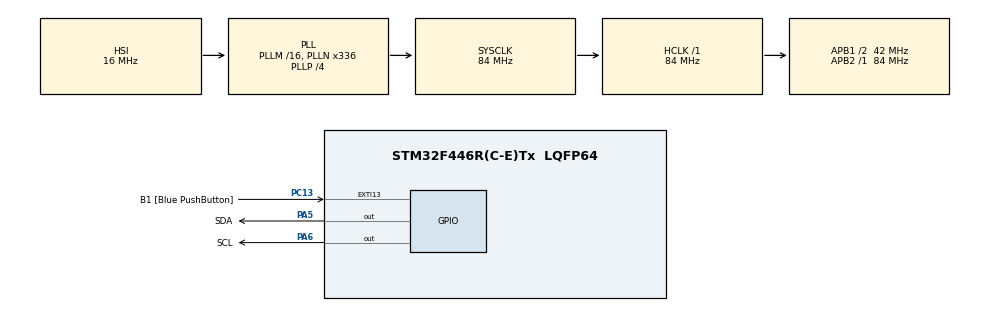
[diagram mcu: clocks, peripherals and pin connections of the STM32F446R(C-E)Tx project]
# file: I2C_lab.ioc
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Mcu.Family=STM32F4
Mcu.Name=STM32F446R(C-E)Tx
Mcu.Package=LQFP64
NVIC.PriorityGroup=NVIC_PRIORITYGROUP_0
NVIC.TIM1_UP_TIM10_IRQn=true\:0\:0\:false\:false\:true\:true\:true\:true
PA13.GPIO_Label=TMS
PA13.Mode=Serial_Wire
PA13.Signal=SYS_JTMS-SWDIO
PA14.GPIO_Label=TCK
PA14.Mode=Serial_Wire
PA14.Signal=SYS_JTCK-SWCLK
PA5.GPIO_Label=SDA
PA5.GPIO_ModeDefaultOutputPP=GPIO_MODE_OUTPUT_OD
PA5.GPIO_PuPd=GPIO_PULLUP
PA5.PinState=GPIO_PIN_SET
PA5.Signal=GPIO_Output
PA6.GPIO_Label=SCL
PA6.GPIO_ModeDefaultOutputPP=GPIO_MODE_OUTPUT_OD
PA6.GPIO_PuPd=GPIO_PULLUP
PA6.PinState=GPIO_PIN_SET
PA6.Signal=GPIO_Output
PB3.GPIO_Label=SWO
PB3.Signal=SYS_JTDO-SWO
PC13.GPIO_Label=B1 [Blue PushButton]
PC13.GPIO_ModeDefaultEXTI=GPIO_MODE_IT_FALLING
PC13.Signal=GPXTI13
PC14-OSC32_IN.Mode=LSE-External-Oscillator
PC14-OSC32_IN.Signal=RCC_OSC32_IN
PC15-OSC32_OUT.Mode=LSE-External-Oscillator
PC15-OSC32_OUT.Signal=RCC_OSC32_OUT
PH0-OSC_IN.Mode=HSE-External-Oscillator
PH0-OSC_IN.Signal=RCC_OSC_IN
PH1-OSC_OUT.Mode=HSE-External-Oscillator
PH1-OSC_OUT.Signal=RCC_OSC_OUT
ProjectManager.HeapSize=0x200
ProjectManager.StackSize=0x400
ProjectManager.TargetToolchain=STM32CubeIDE
RCC.48MHZClocksFreq_Value=84000000
RCC.AHBFreq_Value=84000000
RCC.APB1CLKDivider=RCC_HCLK_DIV2
RCC.APB1Freq_Value=42000000
RCC.APB1TimFreq_Value=84000000
RCC.APB2Freq_Value=84000000
RCC.APB2TimFreq_Value=84000000
RCC.CortexFreq_Value=84000000
RCC.FLatency-AdvancedSettings=FLASH_LATENCY_2
RCC.HCLKFreq_Value=84000000
RCC.HSE_VALUE=8000000
RCC.HSI_VALUE=16000000
RCC.PLLN=336
RCC.PLLP=RCC_PLLP_DIV4
RCC.SYSCLKFreq_VALUE=84000000
RCC.SYSCLKSource=RCC_SYSCLKSOURCE_PLLCLK
RCC.USBFreq_Value=168000000
RCC.VCOOutputFreq_Value=336000000
TIM1.Period=499
TIM1.Prescaler=15999
TIM1.TIM_MasterOutputTrigger=TIM_TRGO_UPDATE
VP_TIM1_VS_ClockSourceINT.Mode=Internal
board=NUCLEO-F446RE

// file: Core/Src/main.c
/* USER CODE BEGIN Header */
/**
  ******************************************************************************
  * @file           : main.c
  * @brief          : Main program body
  ******************************************************************************
  * @attention
  *
  * Copyright (c) 2026 STMicroelectronics.
  * All rights reserved.
  *
  * This software is licensed under terms that can be found in the LICENSE file
  * in the root directory of this software component.
  * If no LICENSE file comes with this software, it is provided AS-IS.
  *
  ******************************************************************************
  */
/* USER CODE END Header */
#include "main.h"

/* USER CODE BEGIN PTD */
typedef enum {
    I2C_IDLE,
    I2C_SEND_ADDRESS, // consists of target + R/W bit
    I2C_WAIT_ADDRESS_ACK,
    I2C_SEND_DATA,
    I2C_WAIT_DATA_ACK,
    I2C_STOP
} I2C_State;

/* USER CODE END PTD */

TIM_HandleTypeDef htim1;

/* USER CODE BEGIN PV */
volatile uint16_t clk_cycle_position; // 0=1st half of low, 1=2nd half of low,
									  // 2=1st half of high, 3=2nd half of high

volatile I2C_State i2c_state = I2C_IDLE;
volatile int8_t bit_position;
volatile uint8_t bit;

uint8_t target_write_address = 0b10100000;
uint8_t data = 0b01010111;

/* USER CODE END PV */

void SystemClock_Config(void);
static void MX_GPIO_Init(void);
static void MX_TIM1_Init(void);

/* USER CODE BEGIN 0 */
void HAL_TIM_PeriodElapsedCallback(TIM_HandleTypeDef *htim)
{
    if (htim->Instance == TIM1) {
    	if (clk_cycle_position == 0) {
    		clk_cycle_position = 1;

    		// transmit data based on i2c_state
    		if (i2c_state == I2C_SEND_ADDRESS) {
    			if (bit_position >= 0) {
    				bit = (target_write_address >> bit_position) & 1;
    				HAL_GPIO_WritePin(GPIOA, SDA_Pin, bit == 1? GPIO_PIN_SET : GPIO_PIN_RESET);
    				bit_position--;
    			} else {
    				i2c_state = I2C_WAIT_ADDRESS_ACK;
					HAL_GPIO_WritePin(GPIOA, SDA_Pin, GPIO_PIN_SET); // release data line
    			}
    		} else if (i2c_state == I2C_WAIT_ADDRESS_ACK) {
    			if (HAL_GPIO_ReadPin(GPIOA, SDA_Pin) == GPIO_PIN_RESET) {
    				i2c_state = I2C_SEND_DATA;
    			} else {
    				i2c_state = I2C_WAIT_ADDRESS_ACK;
    			}
    		} else if (i2c_state == I2C_SEND_DATA) {
    			if (bit_position >= 0) {
    				bit = (data >> bit_position) & 1;
    				HAL_GPIO_WritePin(GPIOA, SDA_Pin, bit == 1 ? GPIO_PIN_SET : GPIO_PIN_RESET);
    				bit_position--;
    			} else {
					i2c_state = I2C_WAIT_DATA_ACK;
					HAL_GPIO_WritePin(GPIOA, SDA_Pin, GPIO_PIN_SET); // release data line
					bit_position = 7;
    			}
    		} else if (i2c_state == I2C_WAIT_DATA_ACK) {
    			if (HAL_GPIO_ReadPin(GPIOA, SDA_Pin) == GPIO_PIN_RESET) {
    				i2c_state = I2C_STOP;
    			} else {
    				I2C_WAIT_DATA_ACK;
    			}
    		}
    	} else if (clk_cycle_position == 1) {
    		clk_cycle_position = 2;
    		HAL_GPIO_WritePin(GPIOA, SCL_Pin, GPIO_PIN_SET);
    	} else if (clk_cycle_position == 2) {
    		clk_cycle_position = 3;
    	} else { // clk_cycle_position == 3
    		clk_cycle_position = 0;
    		HAL_GPIO_WritePin(GPIOA, SCL_Pin, GPIO_PIN_RESET);
    	}
    }
}
/* USER CODE END 0 */

int main(void)
{

  /* MCU Configuration--------------------------------------------------------*/

  /* Reset of all peripherals, Initializes the Flash interface and the Systick. */
  HAL_Init();

  /* Configure the system clock */
  SystemClock_Config();

  /* Initialize all configured peripherals */
  MX_GPIO_Init();
  MX_TIM1_Init();
  /* USER CODE BEGIN 2 */
  HAL_GPIO_WritePin(GPIOA, SDA_Pin, GPIO_PIN_RESET); // write start signal
  bit_position = 7;

  /* USER CODE END 2 */

  /* Infinite loop */
  while (1)
  {

    /* USER CODE BEGIN 3 */
	if (i2c_state == I2C_IDLE &&
		(HAL_GPIO_ReadPin(GPIOA, SCL_Pin) == GPIO_PIN_SET) &&
		(HAL_GPIO_ReadPin(GPIOA, SDA_Pin) == GPIO_PIN_RESET)) {

		i2c_state = I2C_SEND_ADDRESS;

		clk_cycle_position = 0;
		HAL_GPIO_WritePin(GPIOA, SCL_Pin, GPIO_PIN_RESET);// clk line low
		HAL_TIM_Base_Start_IT(&htim1); // start interrupt timer
	} else if (i2c_state == I2C_WAIT_ADDRESS_ACK) {
		HAL_GPIO_WritePin(GPIOA, SDA_Pin, GPIO_PIN_RESET); // low for ack
		bit_position = 7;
	} else if (i2c_state == I2C_WAIT_DATA_ACK) {
		HAL_GPIO_WritePin(GPIOA, SDA_Pin, GPIO_PIN_RESET); // low for ack
		bit_position = 7;
	} else if (i2c_state == I2C_STOP) {
		i2c_state = I2C_IDLE;
		HAL_GPIO_WritePin(GPIOA, SDA_Pin, GPIO_PIN_SET);
		HAL_TIM_Base_Stop_IT(&htim1); // put clk line high until next tx
		HAL_GPIO_WritePin(GPIOA, SCL_Pin, GPIO_PIN_SET);
		HAL_Delay(1500);
		HAL_GPIO_WritePin(GPIOA, SDA_Pin, GPIO_PIN_RESET); // start tx again
	}
  }
  /* USER CODE END 3 */
}

void SystemClock_Config(void)
{
  RCC_OscInitTypeDef RCC_OscInitStruct = {0};
  RCC_ClkInitTypeDef RCC_ClkInitStruct = {0};

  /** Configure the main internal regulator output voltage
  */
  __HAL_RCC_PWR_CLK_ENABLE();
  __HAL_PWR_VOLTAGESCALING_CONFIG(PWR_REGULATOR_VOLTAGE_SCALE3);

  /** Initializes the RCC Oscillators according to the specified parameters
  * in the RCC_OscInitTypeDef structure.
  */
  RCC_OscInitStruct.OscillatorType = RCC_OSCILLATORTYPE_HSI;
  RCC_OscInitStruct.HSIState = RCC_HSI_ON;
  RCC_OscInitStruct.HSICalibrationValue = RCC_HSICALIBRATION_DEFAULT;
  RCC_OscInitStruct.PLL.PLLState = RCC_PLL_ON;
  RCC_OscInitStruct.PLL.PLLSource = RCC_PLLSOURCE_HSI;
  RCC_OscInitStruct.PLL.PLLM = 16;
  RCC_OscInitStruct.PLL.PLLN = 336;
  RCC_OscInitStruct.PLL.PLLP = RCC_PLLP_DIV4;
  RCC_OscInitStruct.PLL.PLLQ = 2;
  RCC_OscInitStruct.PLL.PLLR = 2;
  if (HAL_RCC_OscConfig(&RCC_OscInitStruct) != HAL_OK)
  {
    Error_Handler();
  }

  /** Initializes the CPU, AHB and APB buses clocks
  */
  RCC_ClkInitStruct.ClockType = RCC_CLOCKTYPE_HCLK|RCC_CLOCKTYPE_SYSCLK
                              |RCC_CLOCKTYPE_PCLK1|RCC_CLOCKTYPE_PCLK2;
  RCC_ClkInitStruct.SYSCLKSource = RCC_SYSCLKSOURCE_PLLCLK;
  RCC_ClkInitStruct.AHBCLKDivider = RCC_SYSCLK_DIV1;
  RCC_ClkInitStruct.APB1CLKDivider = RCC_HCLK_DIV2;
  RCC_ClkInitStruct.APB2CLKDivider = RCC_HCLK_DIV1;

  if (HAL_RCC_ClockConfig(&RCC_ClkInitStruct, FLASH_LATENCY_2) != HAL_OK)
  {
    Error_Handler();
  }
}

static void MX_TIM1_Init(void)
{

  TIM_ClockConfigTypeDef sClockSourceConfig = {0};
  TIM_MasterConfigTypeDef sMasterConfig = {0};

  htim1.Instance = TIM1;
  htim1.Init.Prescaler = 15999;
  htim1.Init.CounterMode = TIM_COUNTERMODE_UP;
  htim1.Init.Period = 1499;
  htim1.Init.ClockDivision = TIM_CLOCKDIVISION_DIV1;
  htim1.Init.RepetitionCounter = 0;
  htim1.Init.AutoReloadPreload = TIM_AUTORELOAD_PRELOAD_DISABLE;
  if (HAL_TIM_Base_Init(&htim1) != HAL_OK)
  {
    Error_Handler();
  }
  sClockSourceConfig.ClockSource = TIM_CLOCKSOURCE_INTERNAL;
  if (HAL_TIM_ConfigClockSource(&htim1, &sClockSourceConfig) != HAL_OK)
  {
    Error_Handler();
  }
  sMasterConfig.MasterOutputTrigger = TIM_TRGO_UPDATE;
  sMasterConfig.MasterSlaveMode = TIM_MASTERSLAVEMODE_DISABLE;
  if (HAL_TIMEx_MasterConfigSynchronization(&htim1, &sMasterConfig) != HAL_OK)
  {
    Error_Handler();
  }

}

static void MX_GPIO_Init(void)
{
  GPIO_InitTypeDef GPIO_InitStruct = {0};

  /* GPIO Ports Clock Enable */
  __HAL_RCC_GPIOC_CLK_ENABLE();
  __HAL_RCC_GPIOH_CLK_ENABLE();
  __HAL_RCC_GPIOA_CLK_ENABLE();
  __HAL_RCC_GPIOB_CLK_ENABLE();

  /*Configure GPIO pin Output Level */
  HAL_GPIO_WritePin(GPIOA, SDA_Pin|SCL_Pin, GPIO_PIN_SET);

  /*Configure GPIO pin : B1_Pin */
  GPIO_InitStruct.Pin = B1_Pin;
  GPIO_InitStruct.Mode = GPIO_MODE_IT_FALLING;
  GPIO_InitStruct.Pull = GPIO_NOPULL;
  HAL_GPIO_Init(B1_GPIO_Port, &GPIO_InitStruct);

  /*Configure GPIO pins : SDA_Pin SCL_Pin */
  GPIO_InitStruct.Pin = SDA_Pin|SCL_Pin;
  GPIO_InitStruct.Mode = GPIO_MODE_OUTPUT_OD;
  GPIO_InitStruct.Pull = GPIO_PULLUP;
  GPIO_InitStruct.Speed = GPIO_SPEED_FREQ_LOW;
  HAL_GPIO_Init(GPIOA, &GPIO_InitStruct);

}

void Error_Handler(void)
{
  __disable_irq();
  while (1)
  {
  }
}
